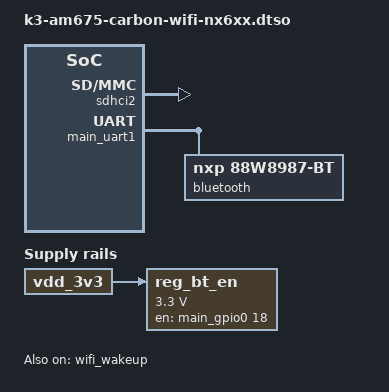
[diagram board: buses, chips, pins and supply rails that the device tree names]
// SPDX-License-Identifier: (GPL-2.0+ OR MIT)
/*
 * Copyright 2024 Ezurio
 */

#include <dt-bindings/gpio/gpio.h>
#include "k3-pinctrl.h"

/dts-v1/;
/plugin/;

&{/} {
	reg_bt_en: regulator-bt-en {
		compatible = "regulator-fixed";

		regulator-name = "reg_bt_en";
		regulator-min-microvolt = <3300000>;
		regulator-max-microvolt = <3300000>;

		vin-supply = <&vdd_3v3>;

		pinctrl-names = "default";
		pinctrl-0 = <&main_bt_en_pins_default>;
		gpios = <&main_gpio0 18 GPIO_ACTIVE_HIGH>;
		enable-active-high;
	};
};

&reg_wifi_en {
	status = "okay";
	startup-delay-us = <20000>;
	vin-supply = <&reg_bt_en>;
	regulator-always-on;
};

&sdhci2 { /* SDIO_B  WIFI */
	status = "okay";
};

&main_uart1 {
	status = "okay";

	bluetooth {
		compatible = "nxp,88w8987-bt";
		fw-init-baudrate = <3000000>;
	};
};

&wifi_wakeup {
	status = "okay";
};
